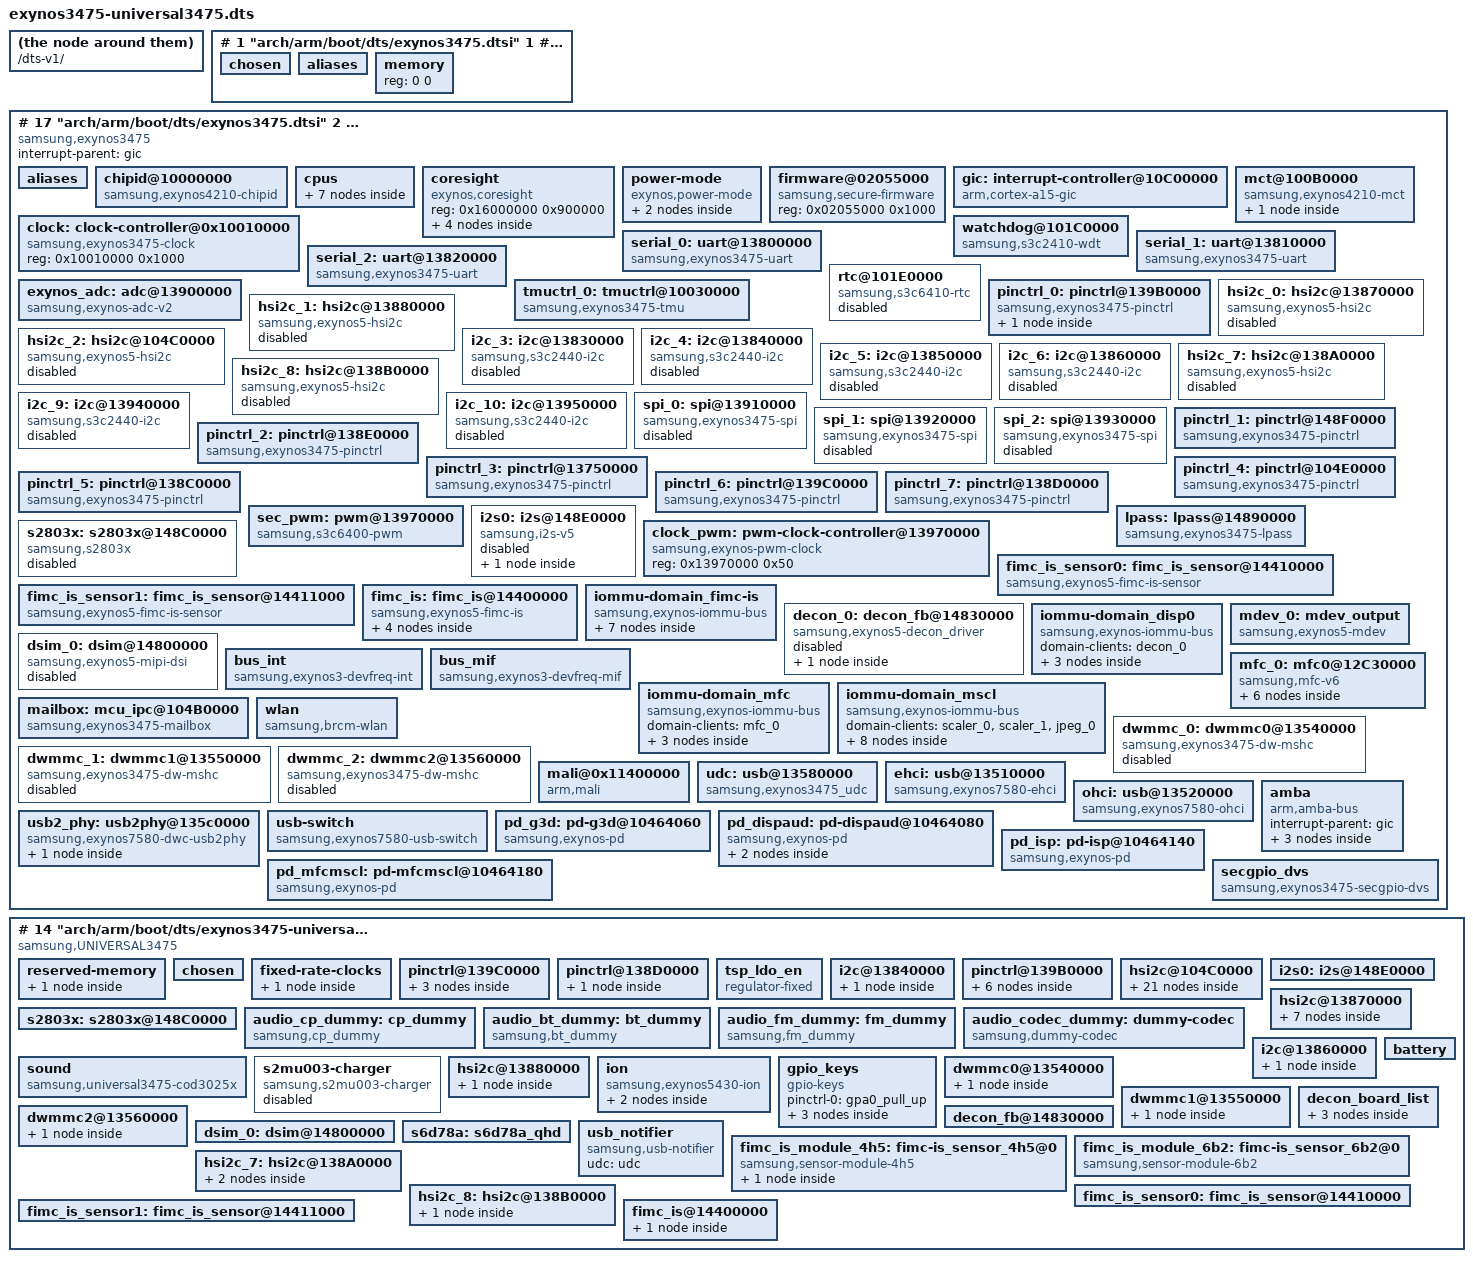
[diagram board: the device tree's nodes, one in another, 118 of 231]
# 1 "arch/arm/boot/dts/exynos3475-universal3475.dts"
# 1 "<command-line>"
# 1 "arch/arm/boot/dts/exynos3475-universal3475.dts"
# 12 "arch/arm/boot/dts/exynos3475-universal3475.dts"
/dts-v1/;
# 1 "arch/arm/boot/dts/exynos3475.dtsi" 1
# 16 "arch/arm/boot/dts/exynos3475.dtsi"
# 1 "arch/arm/boot/dts/skeleton.dtsi" 1






/ {
 #address-cells = <1>;
 #size-cells = <1>;
 chosen { };
 aliases { };
 memory { device_type = "memory"; reg = <0 0>; };
};
# 17 "arch/arm/boot/dts/exynos3475.dtsi" 2
# 1 "/home/dpi/qb5_8814/workspace/J2LTE_SWA_OPEN/android/kernel/exynos3475/arch/arm/boot/dts/include/dt-bindings/clock/exynos3475.h" 1
# 18 "arch/arm/boot/dts/exynos3475.dtsi" 2
# 1 "/home/dpi/qb5_8814/workspace/J2LTE_SWA_OPEN/android/kernel/exynos3475/arch/arm/boot/dts/include/dt-bindings/sysmmu/sysmmu.h" 1
# 19 "arch/arm/boot/dts/exynos3475.dtsi" 2
/include/ "exynos3475-pinctrl.dtsi"
/include/ "exynos3475-busmon.dtsi"
/ {
 compatible = "samsung,exynos3475";

 interrupt-parent = <&gic>;
 #address-cells = <1>;
 #size-cells = <1>;

 aliases {
  mdev0 = &mdev_0;
  dsim0 = &dsim_0;
  decon0 = &decon_0;
  pinctrl0 = &pinctrl_0;
  pinctrl1 = &pinctrl_1;
  pinctrl2 = &pinctrl_2;
  pinctrl3 = &pinctrl_3;
  pinctrl4 = &pinctrl_4;
  pinctrl5 = &pinctrl_5;
  pinctrl6 = &pinctrl_6;
  pinctrl7 = &pinctrl_7;
  uart0 = &serial_0;
  uart1 = &serial_1;
  uart2 = &serial_2;
  mshc0 = &dwmmc_0;
  mshc1 = &dwmmc_1;
  mshc2 = &dwmmc_2;
  spi0 = &spi_0;
  spi1 = &spi_1;
  spi2 = &spi_2;
  scaler0 = &scaler_0;
  scaler1 = &scaler_1;
  mfc0 = &mfc_0;
  jpeg0 = &jpeg_0;
  tmuctrl0 = &tmuctrl_0;
 };

 chipid@10000000 {
  compatible = "samsung,exynos4210-chipid";
  reg = <0x10000000 0x100>;
  reg2 = <0x10004000 0x100>;
 };

 cpus {
  #address-cells = <1>;
  #size-cells = <0>;
  idle-states {
   CPU_SLEEP_0: C1 {
    compatible = "arm,idle-state";
    desc = "ARM Clock gating(WFI)";
    exit-latency-us = <1>;
    min-residency-us = <500>;
    status = "enabled";
   };

                       CPU_SLEEP_1: C2 {
                               compatible = "arm,idle-state";
                               desc = "ARM Power down";
                               exit-latency-us = <50>;
                               min-residency-us = <2100>;
                               status = "enabled";
                       };
  };

  cpu@0 {
   device_type = "cpu";
   compatible = "arm,cortex-a7";
   reg = <0x0>;
   cpu-idle-states = <&CPU_SLEEP_0 &CPU_SLEEP_1>;
  };
  cpu@1 {
   device_type = "cpu";
   compatible = "arm,cortex-a7";
   reg = <0x1>;
   cpu-idle-states = <&CPU_SLEEP_0 &CPU_SLEEP_1>;
  };
  cpu@2 {
   device_type = "cpu";
   compatible = "arm,cortex-a7";
   reg = <0x2>;
   cpu-idle-states = <&CPU_SLEEP_0 &CPU_SLEEP_1>;
  };
  cpu@3 {
   device_type = "cpu";
   compatible = "arm,cortex-a7";
   reg = <0x3>;
   cpu-idle-states = <&CPU_SLEEP_0 &CPU_SLEEP_1>;
  };
 };

 coresight {
  compatible = "exynos,coresight";
  reg = <0x16000000 0x900000>;
  #address-cells = <1>;
  #size-cells = <0>;
  css_pc@0 {
   device_type = "cs";
   offset = <0x810000>;
  };
  css_pc@1 {
   device_type = "cs";
   offset = <0x812000>;
  };
  css_pc@2 {
   device_type = "cs";
   offset = <0x814000>;
  };
  css_pc@3 {
   device_type = "cs";
   offset = <0x816000>;
  };
 };

 power-mode {
  compatible = "exynos,power-mode";
  idle-ip0 = "13970000.pwm",
   "13900000.adc",
   "13870000.hsi2c",
   "13880000.hsi2c",
   "104c0000.hsi2c",
   "138a0000.hsi2c",
   "138b0000.hsi2c",
   "13830000.i2c",
   "13840000.i2c",
   "13850000.i2c",
   "13860000.i2c",
   "13940000.i2c",
   "13950000.i2c",
   "13910000.spi",
   "13920000.spi",
   "13930000.spi",
   "13540000.dwmmc0",
   "13550000.dwmmc1",
   "13560000.dwmmc2",
   "135c0000.usb2phy",
   "13650000.pdma0",
   "13660000.pdma1",
   "148D0000.adma";
  idle-ip1 = "pd-g3d", "pd-isp", "pd-dispaud", "pd-mfcmscl";
  sys_powermode {
   lpd: SYS_LPD {
    mode-index = <2>;
    idle-ip0-mask = <0xffc0fa80>;
    idle-ip1-mask = <0xfffffff4>;
   };
  };
 };

 firmware@02055000 {
  compatible = "samsung,secure-firmware";
  reg = <0x02055000 0x1000>;
 };

 gic:interrupt-controller@10C00000 {
  compatible = "arm,cortex-a15-gic";
  #interrupt-cells = <3>;
  interrupt-controller;
  reg = <0x10C01000 0x1000>,
   <0x10C02000 0x1000>,
   <0x10C04000 0x2000>,
   <0x10C06000 0x2000>;
  interrupts = <1 9 0xf04>;
 };

 clock: clock-controller@0x10010000 {
  compatible = "samsung,exynos3475-clock";
  reg = <0x10010000 0x1000>;
  #clock-cells = <1>;
 };

 mct@100B0000 {
  compatible = "samsung,exynos4210-mct";
  reg = <0x100B0000 0x800>;
  interrupt-controller;
  #interrupt-cells = <1>;
  interrupt-parent = <&mct_map>;
  interrupts = <0>, <1>, <2>, <3>,
        <4>, <5>, <6>, <7>,
        <8>, <9>, <10>, <11>;
  clocks = <&clock 437>, <&clock 318>;
  clock-names = "fin_pll", "mct";

  mct_map: mct-map {
   #interrupt-cells = <1>;
   #address-cells = <0>;
   #size-cells = <0>;
   interrupt-map = <0 &gic 0 102 0>,
     <1 &gic 0 103 0>,
     <2 &gic 0 104 0>,
     <3 &gic 0 105 0>,
     <4 &gic 0 106 0>,
     <5 &gic 0 107 0>,
     <6 &gic 0 108 0>,
     <7 &gic 0 109 0>,
     <8 &gic 0 110 0>,
     <9 &gic 0 111 0>,
     <10 &gic 0 112 0>,
     <11 &gic 0 113 0>;
  };
 };

 watchdog@101C0000 {
  compatible = "samsung,s3c2410-wdt";
  reg = <0x101C0000 0x100>;
  interrupts = <0 100 0>;
  clocks = <&clock 317>, <&clock 317>;
  clock-names = "rate_watchdog", "gate_watchdog";
  timeout-sec = <30>;
  pmu_wdt_reset_type = <4>;
 };

 serial_0: uart@13800000 {
  compatible = "samsung,exynos3475-uart";
  samsung,separate-uart-clk;
  reg = <0x13800000 0x100>;
  interrupts = <0 421 0>;
  pinctrl-names = "default";
  pinctrl-0 = <&uart0_bus>;
  clocks = <&clock 357>, <&clock 361>, <&clock 410>;
  clock-names = "gate_pclk0", "gate_uart0", "sclk_uart0";
 };

 serial_1: uart@13810000 {
  compatible = "samsung,exynos3475-uart";
  samsung,separate-uart-clk;
  reg = <0x13810000 0x100>;
  interrupts = <0 422 0>;
  pinctrl-names = "default";
  pinctrl-0 = <&uart1_bus>;
  clocks = <&clock 356>, <&clock 362>, <&clock 411>;
  clock-names = "gate_pclk1", "gate_uart1", "sclk_uart1";
 };

 serial_2: uart@13820000 {
  compatible = "samsung,exynos3475-uart";
  samsung,separate-uart-clk;
  reg = <0x13820000 0x100>;
  interrupts = <0 423 0>;
  pinctrl-names = "default";
  pinctrl-0 = <&uart2_bus>;
  clocks = <&clock 355>, <&clock 363>, <&clock 412>;
  clock-names = "gate_pclk2", "gate_uart2", "sclk_uart2";
 };

 rtc@101E0000 {
  compatible = "samsung,s3c6410-rtc";
  reg = <0x101E0000 0x100>;
  interrupts = <0 124 0>, <0 125 0>;
  clocks = <&clock 339>;
  clock-names = "gate_rtc";
  status = "disabled";
 };

 exynos_adc: adc@13900000 {
  compatible = "samsung,exynos-adc-v2";
  reg = <0x13900000 0x100>;
  interrupts = <0 439 0>;
  #io-channel-cells = <1>;
  io-channel-ranges;
  clocks = <&clock 354>;
  clock-names = "gate_adcif";
 };

 tmuctrl_0: tmuctrl@10030000 {
  compatible = "samsung,exynos3475-tmu";
  reg = <0x10030000 0x200>;
  interrupts = <0 435 0>;
 };

 pinctrl_0: pinctrl@139B0000 {
  compatible = "samsung,exynos3475-pinctrl";
  reg = <0x139B0000 0x1000>;
  interrupts = <0 0 0>, <0 1 0>, <0 2 0>, <0 3 0>,
    <0 4 0>, <0 5 0>, <0 6 0>, <0 7 0>,
    <0 8 0>, <0 9 0>, <0 10 0>, <0 11 0>,
    <0 12 0>, <0 13 0>, <0 14 0>, <0 15 0>;
  wakeup-interrupt-controller {
   compatible = "samsung,exynos4210-wakeup-eint";
   interrupt-parent = <&gic>;
   interrupts = <0 16 0>;
   samsung,eint-flt-conf;
  };
 };

 hsi2c_0: hsi2c@13870000 {
  compatible = "samsung,exynos5-hsi2c";
  samsung,check-transdone-int;
  reg = <0x13870000 0x1000>;
  interrupts = <0 428 0>;
  #address-cells = <1>;
  #size-cells = <0>;
  pinctrl-names = "default";
  pinctrl-0 = <&hs_i2c0_bus>;
  clocks = <&clock 307>, <&clock 307>;
  clock-names = "rate_hsi2c", "gate_hsi2c";
  samsung,scl-clk-stretching;
  gpio_sda = <&gpc1 0 0x1>;
  gpio_scl = <&gpc1 1 0x1>;
  status = "disabled";
 };

 hsi2c_1: hsi2c@13880000 {
  compatible = "samsung,exynos5-hsi2c";
  samsung,check-transdone-int;
  reg = <0x13880000 0x1000>;
  interrupts = <0 429 0>;
  #address-cells = <1>;
  #size-cells = <0>;
  pinctrl-names = "default";
  pinctrl-0 = <&hs_i2c1_bus>;
  clocks = <&clock 306>, <&clock 306>;
  clock-names = "rate_hsi2c", "gate_hsi2c";
  samsung,scl-clk-stretching;
  gpio_sda = <&gpc1 2 0x1>;
  gpio_scl = <&gpc1 3 0x1>;
  status = "disabled";
 };


 hsi2c_2: hsi2c@104C0000 {
  compatible = "samsung,exynos5-hsi2c";
  samsung,check-transdone-int;
  reg = <0x104C0000 0x2000>, <0x104b01C0 0x100>;
  interrupts = <0 384 0>,<0 394 0>;
  #address-cells = <1>;
  #size-cells = <0>;
  pinctrl-names = "default";
  pinctrl-0 = <&hs_i2c2_bus>;
  clocks = <&clock 286>, <&clock 286>;
  clock-names = "rate_hsi2c", "gate_hsi2c";
  samsung,scl-clk-stretching;
  gpio_sda = <&gpm0 0 0x1>;
  gpio_scl = <&gpm0 1 0x1>;
  status = "disabled";
 };

 i2c_3: i2c@13830000 {
  compatible = "samsung,s3c2440-i2c";
  reg = <0x13830000 0x1000>;
  interrupts = <0 424 0>;
  #address-cells = <1>;
  #size-cells = <0>;
  pinctrl-names = "default";
  pinctrl-0 = <&i2c3_bus>;
  clocks = <&clock 311>, <&clock 311>;
  clock-names = "rate_i2c","gate_i2c";
  status = "disabled";
 };

 i2c_4: i2c@13840000 {
  compatible = "samsung,s3c2440-i2c";
  reg = <0x13840000 0x1000>;
  interrupts = <0 425 0>;
  #address-cells = <1>;
  #size-cells = <0>;
  pinctrl-names = "default";
  pinctrl-0 = <&i2c4_bus>;
  clocks = <&clock 310>, <&clock 310>;
  clock-names = "rate_i2c","gate_i2c";
  status = "disabled";
 };

 i2c_5: i2c@13850000 {
  compatible = "samsung,s3c2440-i2c";
  reg = <0x13850000 0x1000>;
  interrupts = <0 426 0>;
  #address-cells = <1>;
  #size-cells = <0>;
  pinctrl-names = "default";
  pinctrl-0 = <&i2c5_bus>;
  clocks = <&clock 309>, <&clock 309>;
  clock-names = "rate_i2c","gate_i2c";
  status = "disabled";
 };

 i2c_6: i2c@13860000 {
  compatible = "samsung,s3c2440-i2c";
  reg = <0x13860000 0x1000>;
  interrupts = <0 427 0>;
  #address-cells = <1>;
  #size-cells = <0>;
  pinctrl-names = "default";
  pinctrl-0 = <&i2c6_bus>;
  clocks = <&clock 308>, <&clock 308>;
  clock-names = "rate_i2c","gate_i2c";
  status = "disabled";
 };

 hsi2c_7: hsi2c@138A0000 {
  compatible = "samsung,exynos5-hsi2c";
  samsung,check-transdone-int;
  reg = <0x138A0000 0x1000>;
  interrupts = <0 430 0>;
  #address-cells = <1>;
  #size-cells = <0>;
  pinctrl-names = "default";
  pinctrl-0 = <&hs_i2c7_bus>;
  clocks = <&clock 305>, <&clock 305>;
  clock-names = "rate_hsi2c", "gate_hsi2c";
  samsung,scl-clk-stretching;
  gpio_sda = <&gpf0 0 0x1>;
  gpio_scl = <&gpf0 1 0x1>;
  status = "disabled";
 };

 hsi2c_8: hsi2c@138B0000 {
  compatible = "samsung,exynos5-hsi2c";
  samsung,check-transdone-int;
  reg = <0x138B0000 0x1000>;
  interrupts = <0 431 0>;
  #address-cells = <1>;
  #size-cells = <0>;
  pinctrl-names = "default";
  pinctrl-0 = <&hs_i2c8_bus>;
  clocks = <&clock 304>, <&clock 304>;
  clock-names = "rate_hsi2c", "gate_hsi2c";
  samsung,scl-clk-stretching;
  gpio_sda = <&gpf0 2 0x1>;
  gpio_scl = <&gpf0 3 0x1>;
  status = "disabled";
 };

 i2c_9: i2c@13940000 {
  compatible = "samsung,s3c2440-i2c";
  reg = <0x13940000 0x1000>;
  interrupts = <0 436 0>;
  #address-cells = <1>;
  #size-cells = <0>;
  pinctrl-names = "default";
  pinctrl-0 = <&i2c9_bus>;
  clocks = <&clock 350>, <&clock 350>;
  clock-names = "rate_i2c","gate_i2c";
  status = "disabled";
 };

 i2c_10: i2c@13950000 {
  compatible = "samsung,s3c2440-i2c";
  reg = <0x13950000 0x1000>;
  interrupts = <0 437 0>;
  #address-cells = <1>;
  #size-cells = <0>;
  pinctrl-names = "default";
  pinctrl-0 = <&i2c10_bus>;
  clocks = <&clock 349>, <&clock 349>;
  clock-names = "rate_i2c","gate_i2c";
  status = "disabled";
 };

 spi_0: spi@13910000 {
  samsung,ignore-sclk-gate;
  compatible = "samsung,exynos3475-spi";
  reg = <0x13910000 0x100>;
  interrupts = <0 432 0>;






  swap-mode;
  #address-cells = <1>;
  #size-cells = <0>;
  clocks = <&clock 353>, <&clock 358>;
  clock-names = "spi", "spi_busclk0";
  pinctrl-names = "default";
  pinctrl-0 = <&spi0_bus_0 &spi0_bus_1>;
  status = "disabled";
 };

 spi_1: spi@13920000 {
  samsung,ignore-sclk-gate;
  compatible = "samsung,exynos3475-spi";
  reg = <0x13920000 0x100>;
  interrupts = <0 433 0>;






  swap-mode;
  #address-cells = <1>;
  #size-cells = <0>;
  clocks = <&clock 352>, <&clock 359>;
  clock-names = "spi", "spi_busclk0";
  pinctrl-names = "default";
  pinctrl-0 = <&spi1_bus>;
  status = "disabled";
 };

 spi_2: spi@13930000 {
  samsung,ignore-sclk-gate;
  compatible = "samsung,exynos3475-spi";
  reg = <0x13930000 0x100>;
  interrupts = <0 434 0>;






  #address-cells = <1>;
  #size-cells = <0>;
  clocks = <&clock 351>, <&clock 360>;
  clock-names = "spi", "spi_busclk0";
  pinctrl-names = "default";
  pinctrl-0 = <&spi2_bus>;
  status = "disabled";
 };

 pinctrl_1: pinctrl@148F0000 {
  compatible = "samsung,exynos3475-pinctrl";
  reg = <0x148F0000 0x1000>;
  interrupts = <0 68 0>;
 };

 pinctrl_2: pinctrl@138E0000 {
  compatible = "samsung,exynos3475-pinctrl";
  reg = <0x138E0000 0x1000>;
  interrupts = <0 438 0>;
 };

 pinctrl_3: pinctrl@13750000 {
  compatible = "samsung,exynos3475-pinctrl";
  reg = <0x13750000 0x1000>;
  interrupts = <0 250 0>;
 };

 pinctrl_4: pinctrl@104E0000 {
  compatible = "samsung,exynos3475-pinctrl";
  reg = <0x104E0000 0x1000>;
  interrupts = <0 385 0>;
 };

 pinctrl_5: pinctrl@138C0000 {
  compatible = "samsung,exynos3475-pinctrl";
  reg = <0x138C0000 0x1000>;
  interrupts = <0 115 0>;
 };

 pinctrl_6: pinctrl@139C0000 {
  compatible = "samsung,exynos3475-pinctrl";
  reg = <0x139C0000 0x1000>;
  interrupts = <0 440 0>;
 };

 pinctrl_7: pinctrl@138D0000 {
  compatible = "samsung,exynos3475-pinctrl";
  reg = <0x138D0000 0x1000>;
  interrupts = <0 116 0>;
 };

 sec_pwm: pwm@13970000 {
  compatible = "samsung,s3c6400-pwm";
  reg = <0x13970000 0x1000>;
  #pwm-cells = <3>;
  clocks = <&clock 348>,
         <&clock_pwm 1>, <&clock_pwm 2>,
         <&clock_pwm 5>, <&clock_pwm 6>,
         <&clock_pwm 7>, <&clock_pwm 8>,
         <&clock_pwm 10>, <&clock_pwm 11>,
         <&clock_pwm 12>, <&clock_pwm 13>;
  clock-names = "gate_timers",
   "pwm-scaler0", "pwm-scaler1",
   "pwm-tdiv0", "pwm-tdiv1",
   "pwm-tdiv2", "pwm-tdiv3",
   "pwm-tin0", "pwm-tin1",
   "pwm-tin2", "pwm-tin3";
  status = "ok";
  clock-control = <1>;
 };

 lpass: lpass@14890000 {
  compatible = "samsung,exynos3475-lpass";
  reg = <0x14890000 0x1040>;
  clocks = <&clock 195>,
   <&clock 437>,
   <&clock 62>,
   <&clock 64>,
   <&clock 67>,
   <&clock 68>,
   <&clock 69>,
   <&clock 70>,
   <&clock 72>;

  clock-names = "fout_aud_pll", "fin_pll", "mout_aud_pll_user",
   "mout_sclk_mi2s", "dout_sclk_mi2s",
   "dout_sclk_mixer", "pclk_dispaud_p", "aclk_aud",
   "aclk_dispaud_d";

  samsung,power-domain = <&spd_aud>;
  status = "okay";
 };

 s2803x: s2803x@148C0000 {
  compatible = "samsung,s2803x";
  reg = <0x148C0000 0x200>;
  clocks = <&clock 80>,
    <&clock 81>,
    <&clock 83>,
    <&clock 82>,
    <&clock 68>,
    <&clock 70>;

  clock-names = "audmixer_sysclk", "audmixer_bclk0",
    "audmixer_bclk1", "audmixer_bclk2",
    "audmixer_dout", "audmixer_aclk";

  samsung,lpass-subip;
  status = "disabled";
 };

 i2s0: i2s@148E0000 {
  compatible = "samsung,i2s-v5";
  reg = <0x148E0000 0x100>;
  dmas = <&adma 0
   &adma 2>;
  dma-names = "tx", "rx";
  interrupts = <0 205 0>;
  clocks = <&clock 70>,
    <&clock 79>,
    <&clock 79>;
  clock-names = "iis", "i2s_opclk0", "i2s_opclk1";
  samsung,supports-rstclr;
  samsung,supports-secdai;
  samsung,i2s-str;
  samsung,lpass-subip;
  status = "disabled";
  i2s-sec {
   dmas = <&adma 1>;
   dma-names = "tx-sec";
   clocks = <&clock 70>,
     <&clock 79>,
     <&clock 79>;
   clock-names = "iis", "i2s_opclk0", "i2s_opclk1";
  };
 };

 clock_pwm: pwm-clock-controller@13970000 {
  compatible = "samsung,exynos-pwm-clock";
  reg = <0x13970000 0x50>;
  #clock-cells = <1>;
 };

 fimc_is_sensor0: fimc_is_sensor@14410000 {
  compatible = "samsung,exynos5-fimc-is-sensor";
  #pb-id-cells = <4>;
  interrupts = <0 138 0>,
     <0 144 0>;

  samsung,power-domain = <&pd_isp>;

  clock-names = "phyclk_csi_link0_rx_byte_clk_hs0",

    "mout_sclk_isp_sensor0",

    "dout_sclk_isp_sensor0_a",
    "dout_sclk_isp_sensor0_b",
    "dout_sclk_isp_sensor1_a",
    "dout_sclk_isp_sensor1_b",

    "sclk_isp_sensor0",

    "oscclk";

  clocks = <&clock 179>,

    <&clock 387>,

    <&clock 413>,
    <&clock 414>,
    <&clock 415>,
    <&clock 416>,

    <&clock 435>,

    <&clock 437>;
 };

 fimc_is_sensor1: fimc_is_sensor@14411000 {
  compatible = "samsung,exynos5-fimc-is-sensor";
  #pb-id-cells = <4>;
  interrupts = <0 138 0>,
     <0 144 0>;

  samsung,power-domain = <&pd_isp>;

  clock-names = "phyclk_csi_link0_rx_byte_clk_hs0",

    "mout_sclk_isp_sensor1",

    "dout_sclk_isp_sensor0_a",
    "dout_sclk_isp_sensor0_b",
    "dout_sclk_isp_sensor1_a",
    "dout_sclk_isp_sensor1_b",

    "sclk_isp_sensor1",

    "oscclk";


  clocks = <&clock 179>,

    <&clock 388>,

    <&clock 413>,
    <&clock 414>,
    <&clock 415>,
    <&clock 416>,

    <&clock 436>,

    <&clock 437>;
 };

 fimc_is: fimc_is@14400000 {
  compatible = "samsung,exynos5-fimc-is";
  #pb-id-cells = <4>;
  reg = <0x14400000 0x10000>,
    <0x14430000 0x10000>,
    <0x14440000 0x10000>,
    <0x14480000 0x10000>;
  interrupts = <0 139 0>,
     <0 140 0>,
     <0 141 0>,
     <0 142 0>,
     <0 143 0>;

  samsung,power-domain = <&pd_isp>;

  clocks = <&clock 171>,
    <&clock 173>,
    <&clock 174>,
    <&clock 175>,
    <&clock 176>,
    <&clock 177>,
    <&clock 179>,

    <&clock 437>;

  clock-names = "mout_aclk_isp_300_user",
       "dout_pclk_isp_150",
       "aclk_isp_300_aclk_isp_d",
       "aclk_isp_300_aclk_ppmu",
       "aclk_isp_300_aclk_fd",
       "aclk_isp_300_aclk_is",
       "phyclk_csi_link0_rx_byte_clk_hs0",

       "oscclk";


  clk_gate_strs = "gate_3aa1",
       "gate_isp",
       "gate_drc",
       "gate_scalerc",
       "gate_dis",
       "gate_3dnr",
       "gate_scalerp",
       "gate_fd",
       "gate_3aa0";

  clk_gate_ctrl {

   group0 {
   };

   group1 {

   };

   group2 {
   };
  };
 };

 iommu-domain_fimc-is {
  compatible = "samsung,exynos-iommu-bus";
  #address-cells = <1>;
  #size-cells = <1>;
  ranges;

  domain-clients = <&fimc_is>,
    <&fimc_is_sensor0>,
    <&fimc_is_sensor1>;

  sysmmu_isp0: sysmmu@0x144A0000 {
    compatible = "samsung,exynos7420-sysmmu";
    reg = <0x144A0000 0x1000>;
    interrupts = <0 128 0>;
    clocks = <&clock 177>;
    clock-names = "aclk";
    sysmmu,block-when-stop;
    pb-info {
    pb@0 {
      master_axi_id_list = <&fimc_is (1) ((0) + 0x8000) ((1) + 0x8000) ((5) + 0x8000)>,
        <&fimc_is_sensor0 (1) ((0) + 0x8000) ((1) + 0x8000) ((5) + 0x8000)>,
        <&fimc_is_sensor1 (1) ((0) + 0x8000) ((1) + 0x8000) ((5) + 0x8000)>;
    };
    pb@1 {
      master_axi_id_list = <&fimc_is ((2) + 0x8000) ((6) + 0x8000) ((10) + 0x8000) 65536>;
    };
    };
   };

  sysmmu_isp1: sysmmu@0x144B0000 {
    compatible = "samsung,exynos7420-sysmmu";
    reg = <0x144B0000 0x1000>;
    interrupts = <0 131 0>;
    clocks = <&clock 176>;
    clock-names = "aclk";
    sysmmu,block-when-stop;
    pb-info {
     pb@0 {
      master_axi_id_list = <&fimc_is 65536 65536 65536 65536>;
     };
   };
  };
 };


 decon_0: decon_fb@14830000 {
  compatible = "samsung,exynos5-decon_driver";
  #pb-id-cells = <0>;
  reg = <0x14830000 0x10000>;


  interrupts = <0 195 0>, <0 196 0>, <0 197 0>;


  clocks =<&clock 72>, <&clock 71>,
         <&clock 75>, <&clock 76>,
         <&clock 65>, <&clock 66>,
         <&clock 58>, <&clock 59>,
         <&clock 208>, <&clock 218>,
         <&clock 207>, <&clock 217>,
         <&clock 193>;

  clock-names =
   "aclk_dispaud_d", "aclk_disp",
   "decon0_vclk", "decon0_eclk",
   "d_decon0_vclk", "d_decon0_eclk",
   "m_sclk_decon_int_vclk_user", "m_sclk_decon_int_eclk_user",
   "m_sclk_disp_decon0_vclk", "d_sclk_disp_decon0_vclk",
   "m_sclk_disp_decon0_eclk", "d_sclk_disp_decon0_eclk",
   "mif_pll";

  ip_ver = <4>;
  max_win = <3>;
  n_sink_pad = <3>;
  n_src_pad = <1>;
  default_win = <0>;
  psr_mode = <0>;
  trig_mode = <0>;
  dsi_mode = <0>;

  samsung,power-domain = <&spd_disp>;
  status = "disabled";

                #address-cells = <1>;
                #size-cells = <1>;
  ranges;

  cam-stat {

   reg = <0x0 0x10464144 0x0 0x4>;
  };

 };

 iommu-domain_disp0 {
  compatible = "samsung,exynos-iommu-bus";
  #address-cells = <1>;
  #size-cells = <1>;
  ranges;

  domain-clients = <&decon_0>;

  sysmmu_disp: sysmmu@0x14860000 {
    compatible = "samsung,exynos7420-sysmmu";
    reg = <0x14860000 0x1000>;
    interrupts = <0 192 0>;
    sysmmu,block-when-stop;
    pb-info {
     pb@0 {
      master_axi_id_list = <&decon_0>;
     };
   };
  };
 };

 mdev_0: mdev_output {
  compatible = "samsung,exynos5-mdev";
 };

 dsim_0: dsim@14800000 {
  compatible = "samsung,exynos5-mipi-dsi";
  reg = <0x14800000 0x1000>;
  interrupts = <0 201 0>;

  clocks = <&clock 77>, <&clock 78>;

  clock-names = "mipi0_bit", "mipi0_rx";

  samsung,power-domain = <&spd_disp>;

  status = "disabled";
 };

 bus_int {
  compatible = "samsung,exynos3-devfreq-int";

  bus_type_int = <0>;

  pm_qos_class = <4>;
  cal_qos_max = <00 275000>;
  default_qos = <00 275000>;
  initial_freq = <00 275000>;
  polling_period = <0>;
 };

 bus_mif {
  compatible = "samsung,exynos3-devfreq-mif";

  bus_type_mif = <1>;

  pm_qos_class = <5>;
  pm_qos_class_max = <6>;
  cal_qos_max = <00 666000>;
  default_qos = <00 413000>;
  initial_freq = <00 666000>;
  polling_period = <0>;
 };

 mfc_0: mfc0@12C30000 {
  compatible = "samsung,mfc-v6";
  #pb-id-cells = <0>;
  reg = <0x12C30000 0x10000>;
  interrupts = <0 358 0>;

  clock-names = "aclk_mfcmscl_333_aclk_mfcmscl_d", "aclk_mfcmscl_200_aclk_mfc";
  clocks = <&clock 184>, <&clock 191>;

  samsung,power-domain = <&pd_mfcmscl>;
  status = "ok";
  ip_ver = <13>;
  clock_rate = <200000000>;
  min_rate = <100000>;

  num_qos_steps = <5>;
  mfc_qos_table {
   mfc_qos_variant_0 {
    thrd_mb = <0>;
    freq_mfc = <100000>;
    freq_int = <275000>;
    freq_mif = <413000>;
    freq_cpu = <0>;
    freq_kfc = <0>;
   };
   mfc_qos_variant_1 {
    thrd_mb = <108000>;
    freq_mfc = <100000>;
    freq_int = <275000>;
    freq_mif = <413000>;
    freq_cpu = <0>;
    freq_kfc = <0>;
    has_enc_table = <0>;
   };
   mfc_qos_variant_2 {
    thrd_mb = <244800>;
    freq_mfc = <200000>;
    freq_int = <275000>;
    freq_mif = <559000>;
    freq_cpu = <0>;
    freq_kfc = <0>;
    has_enc_table = <0>;
   };
   mfc_qos_variant_3 {
    thrd_mb = <244800>;
    freq_mfc = <160000>;
    freq_int = <275000>;
    freq_mif = <413000>;
    freq_cpu = <0>;
    freq_kfc = <0>;
    has_enc_table = <1>;
   };
   mfc_qos_variant_4 {
    thrd_mb = <489600>;
    freq_mfc = <200000>;
    freq_int = <275000>;
    freq_mif = <559000>;
    freq_cpu = <0>;
    freq_kfc = <0>;
    has_enc_table = <0>;
   };
  };
 };

 iommu-domain_mfc {
  compatible = "samsung,exynos-iommu-bus";
  #address-cells = <1>;
  #size-cells = <1>;
  ranges;

  domain-clients = <&mfc_0>;

  sysmmu_mfc: sysmmu@0x12C90000 {
    compatible = "samsung,exynos7420-sysmmu";
    reg = <0x12C90000 0x1000>;
    interrupts = <0 359 0>;
    sysmmu,block-when-stop;
    pb-info {
     pb@0 {
      master_axi_id_list = <&mfc_0>;
     };
   };
  };
 };

 iommu-domain_mscl {
  compatible = "samsung,exynos-iommu-bus";
  #address-cells = <1>;
  #size-cells = <1>;
  ranges;

  domain-clients = <&scaler_0>, <&scaler_1>, <&jpeg_0>;

  scaler_0: scaler@0x12C10000 {
   compatible = "samsung,exynos5-scaler";
   #pb-id-cells = <0>;
   reg = <0x12C10000 0x1300>;
   interrupts = <0 353 0>;
   samsung,power-domain = <&pd_mfcmscl>;
   clocks = <&clock 185>;
   clock-names = "gate";
  };

  scaler_1: scaler@0x12C00000 {
   compatible = "samsung,exynos5-scaler";
   #pb-id-cells = <0>;
   reg = <0x12C00000 0x1300>;
   interrupts = <0 352 0>;
   samsung,power-domain = <&pd_mfcmscl>;
   clocks = <&clock 186>;
   clock-names = "gate";
  };

  jpeg_0: jpeg@12C20000{
   compatible = "samsung,exynos-jpeg";
   #pb-id-cells = <0>;
   reg = <0x12C20000 0x1000>;
   interrupts = <0 357 0>;
   clocks = <&clock 187>;
   clock-names = "gate";
   ip_ver = <2>;
   samsung,power-domain = <&pd_mfcmscl>;
  };

  sysmmu_mscl: sysmmu@0x12C80000 {
    compatible = "samsung,exynos7420-sysmmu";
    reg = <0x12C80000 0x1000>;
    interrupts = <0 354 0>;
    clocks = <&clock 184>, <&clock 188>;
    clock-names = "aclk", "pclk";

    sysmmu,block-when-stop;
    pb-info {
     pb@0 {
      master_axi_id_list = <&scaler_0>;
     };
     pb@1 {
      master_axi_id_list = <&scaler_1>;
     };
     pb@2 {
      master_axi_id_list = <&jpeg_0>;
     };
   };
  };
 };

 mailbox: mcu_ipc@104B0000 {
  compatible = "samsung,exynos3475-mailbox";
  reg = <0x104B0000 0x180>;
  mcu,name = "mcu_ipc";
  mcu,id = <1>;
  interrupts = <0 383 0 >;
 };

 wlan {
  compatible = "samsung,brcm-wlan";
  gpios = <&gpd1 4 0x1
  &gpa1 5 0x1 >;
  pinctrl-names = "default";
  pinctrl-0 = <&cfg_wlanen &cfg_wlanhostwake>;
  status = "okay";
  };

 dwmmc_0: dwmmc0@13540000 {
  compatible = "samsung,exynos3475-dw-mshc";
  reg = <0x13540000 0x2000>;
  interrupts = <0 245 0>;
  #address-cells = <1>;
  #size-cells = <0>;
  clocks = <&clock 117>, <&clock 426>,
         <&clock 398>, <&clock 399>;
  clock-names = "biu", "gate_ciu",
   "dout_mmc_a", "dout_mmc_b";
  status = "disabled";
 };

 dwmmc_1: dwmmc1@13550000 {
  compatible = "samsung,exynos3475-dw-mshc";
  reg = <0x13550000 0x2000>;
  interrupts = <0 246 0>;
  #address-cells = <1>;
  #size-cells = <0>;
  clocks = <&clock 116>, <&clock 427>,
   <&clock 400>, <&clock 401>;
  clock-names = "biu", "gate_ciu",
   "dout_mmc_a", "dout_mmc_b";
  status = "disabled";
 };

 dwmmc_2: dwmmc2@13560000 {
  compatible = "samsung,exynos3475-dw-mshc";
  reg = <0x13560000 0x2000>;
  interrupts = <0 247 0>;
  #address-cells = <1>;
  #size-cells = <0>;
  clocks = <&clock 115>, <&clock 428>,
   <&clock 402>, <&clock 403>;
  clock-names = "biu", "gate_ciu",
   "dout_mmc_a", "dout_mmc_b";
  status = "disabled";
 };

 mali@0x11400000 {
  compatible = "arm,mali";
  reg = <0x11400000 0x5000>;
  interrupts = <0 282 0>, <0 283 0>, <0 281 0>;
  interrupt-names = "JOB", "MMU", "GPU";
  clocks = <&clock 437>, <&clock 130>, <&clock 131>, <&clock 132>, <&clock 139>, <&clock 395>, <&clock 423>;
  clock-names = "fin_pll", "fout_g3d_pll", "mout_aclk_g3d_400_user",
   "mout_aclk_g3d_667", "aclk_g3d", "dout_aclk_g3d_400", "aclk_g3d_400";
  samsung,power-domain = <&pd_g3d>;
 };

 udc: usb@13580000 {
  compatible = "samsung,exynos3475_udc";
  reg = <0x13580000 0x1000>;
  interrupts = <0 238 0>;

  clocks = <&clock 114>, <&clock 113>, <&clock 112>,
    <&clock 110>, <&clock 102>, <&clock 99>,
    <&clock 107>, <&clock 106>;
  clock-names = "otg_aclk", "otg_hclk", "upsizer_otg",
   "xiu_d_fsys1", "upsizer_fsys1", "upsizer_ahb_usbhs",
   "ahb_usbhs", "ahb2axi_usbhs";
  usb-phy = <&usb2_phy>;
 };

 ehci: usb@13510000 {
  compatible = "samsung,exynos7580-ehci";
  reg = <0x13510000 0x100>;
  interrupts = <0 239 0>;
  clocks = <&clock 114>, <&clock 110>, <&clock 107>,
         <&clock 106>, <&clock 102>, <&clock 99>, <&clock 119>;
  clock-names = "otg_aclk", "xiu_d_fsys1", "ahb_usbhs",
   "ahb2axi_usbhs", "upsizer_fsys1", "upsizer_ahb_usbhs","usbhost20";
  usb-phy = <&usb2_phy>;
  status = "ok";
 };

 ohci: usb@13520000 {
  compatible = "samsung,exynos7580-ohci";
  reg = <0x13520000 0x100>;
  clocks = <&clock 114>, <&clock 110>, <&clock 107>,
         <&clock 106>, <&clock 102>, <&clock 99>, <&clock 119>;
  clock-names = "otg_aclk", "xiu_d_fsys1", "ahb_usbhs",
   "ahb2axi_usbhs", "upsizer_fsys1", "upsizer_ahb_usbhs", "usbhost20";
  interrupts = <0 239 0>;
  usb-phy = <&usb2_phy>;
  status = "ok";
 };

 usb2_phy: usb2phy@135c0000 {
  compatible = "samsung,exynos7580-dwc-usb2phy";
  #address-cells = <1>;
  #size-cells = <1>;
  reg = <0x135c0000 0x100>;
  clocks = <&clock 85>, <&clock 93>, <&clock 114>, <&clock 113>,
    <&clock 112>, <&clock 110>, <&clock 102>, <&clock 99>,
    <&clock 126>, <&clock 127>, <&clock 128>;
  clock-names = "usb_pll", "phy_otg", "otg_aclk", "otg_hclk",
      "upsizer_otg", "xiu_d_fsys1", "upsizer_fsys1", "upsizer_ahb_usbhs",
   "freeclk", "phyclk", "clk48mohci";
  ranges;

  usbphy-sys {
   reg = <0x10460738 0xC>,
    <0x13721020 0xC>;
  };
 };

 usb-switch {
  compatible = "samsung,exynos7580-usb-switch";
  ehci = <&ehci>;
  ohci = <&ohci>;
 };

 pd_g3d: pd-g3d@10464060 {
  compatible = "samsung,exynos-pd";
  reg = <0x10464060 0x20>;
  pd-option = <0x1>;
  bts-status = "enabled";
 };

 pd_dispaud: pd-dispaud@10464080 {
  compatible = "samsung,exynos-pd";
  reg = <0x10464080 0x20>;
  pd-option = <0x2>;
  bts-status = "enabled";

  spd_aud: spd-aud@10464080 {
   compatible = "samsung,exynos-spd";
  };

  spd_disp: spd-disp@10464080 {
   compatible = "samsung,exynos-spd";
  };
 };

 pd_isp: pd-isp@10464140 {
  compatible = "samsung,exynos-pd";
  reg = <0x10464140 0x20>;
  pd-option = <0x2>;
  bts-status = "enabled";
 };

 pd_mfcmscl: pd-mfcmscl@10464180 {
  compatible = "samsung,exynos-pd";
  reg = <0x10464180 0x20>;
  pd-option = <0x2>;
  bts-status = "enabled";
 };

 amba {
  #address-cells = <1>;
  #size-cells = <1>;
  compatible = "arm,amba-bus";
  interrupt-parent = <&gic>;
  ranges;

  pdma0: pdma0@13650000 {
   compatible = "arm,pl330", "arm,primecell";
   reg = <0x13650000 0x1000>;
   interrupts = <0 228 0>;
   clocks = <&clock 121>;
   clock-names = "apb_pclk";
   #dma-cells = <1>;
   #dma-channels = <8>;
   #dma-requests = <32>;
  };

  pdma1: pdma1@13660000 {
   compatible = "arm,pl330", "arm,primecell";
   reg = <0x13660000 0x1000>;
   interrupts = <0 229 0>;
   clocks = <&clock 120>;
   clock-names = "apb_pclk";
   #dma-cells = <1>;
   #dma-channels = <4>;
   #dma-requests = <32>;
  };

  adma: adma@148D0000 {
   compatible = "arm,pl330", "arm,primecell";
   reg = <0x148D0000 0x1000>;
   interrupts = <0 204 0>;
   clocks = <&clock 70>;
   clock-names = "apb_pclk";
   #dma-cells = <1>;
   #dma-channels = <4>;
   #dma-requests = <32>;
   samsung,reset-reg = <0x14891000>;
   samsung,reset-bit = <2>;
   samsung,reset-high;
  };
 };

 secgpio_dvs {
  compatible = "samsung,exynos3475-secgpio-dvs";
  status = "okay";
 };
};
# 14 "arch/arm/boot/dts/exynos3475-universal3475.dts" 2

/ {
 model = "Samsung UNIVERSAL3475 board based on EXYNOS3475";
 compatible = "samsung,UNIVERSAL3475", "samsung,exynos3475";

 reserved-memory {
  #address-cells = <1>;
  #size-cells = <1>;
  ranges;

  mfc_nfw {
   compatible = "exynos5433-ion,mfc_nfw";
   size = <0x100000>;
   alignment = <0x100000>;
   id = <12>;
  };
 };

 chosen {
  bootargs = "console=ttySAC2,115200 vmalloc=256M ess_setup=0x26000000";
 };

 fixed-rate-clocks {
  oscclk {
   compatible = "samsung,exynos3475-oscclk";
   clock-frequency = <26000000>;
  };
 };

 pinctrl@139C0000 {
  attn_irq: attn-irq {
   samsung,pins = "gpd1-5";
   samsung,pin-function = <0xf>;
   samsung,pin-pud = <0>;
   samsung,pin-drv = <0>;
  };

  attn_input: attn-input {
   samsung,pins = "gpd1-5";
   samsung,pin-function = <0>;
   samsung,pin-pud = <1>;
   samsung,pin-drv = <0>;
  };
 };

 pinctrl@138D0000 {
  i2c_pdn_off: i2c-pdn_off {
   samsung,pins = "gpc3-1", "gpc3-0";
   samsung,pin-con-pdn = <2>;
   samsung,pin-pud-pdn = <1>;
  };
 };

 tsp_ldo_en {
  compatible = "regulator-fixed";
  regulator-name = "tsp_avdd";
  regulator-min-microvolt = <3000000>;
  regulator-max-microvolt = <3000000>;
  gpio = <&gpc3 2 0>;
  enable-active-high;
  };

 i2c@13840000 {
  samsung,i2c-sda-delay = <100>;
  samsung,i2c-max-bus-freq = <400000>;
  status = "okay";
  touchscreen@20 {
   compatible = "zinitix,bt532_ts_device";
   reg = <0x20>;
   pinctrl-names = "on_state", "off_state";
   pinctrl-0 = <&attn_irq>;
   pinctrl-1 = <&attn_input &i2c_pdn_off>;
   zinitix,irq_gpio = <&gpd1 5 0>;
   zinitix,gpio_ldo_en;
   zinitix,regulator_avdd = "tsp_avdd";
   zinitix,x_resolution = <540>;
   zinitix,y_resolution = <960>;
   zinitix,page_size = <128>;
   zinitix,orientation = <0>;
   zinitix,firmware_name = "tsp_zinitix/bt532_gt58.fw";
  };
 };

 pinctrl@139B0000 {
  pmic_irq: pmic-irq {
   samsung,pins = "gpa1-2";
   samsung,pin-pud = <3>;
   samsung,pin-drv = <3>;
  };

  if_irq: if-irq {
   samsung,pins = "gpa0-2";
   samsung,pin-pud = <3>;
   samsung,pin-drv = <3>;
  };

  cod3025_irq: cod3025-irq {
   samsung,pins = "gpa0-6";
   samsung,pin-pud = <3>;
   samsung,pin-drv = <3>;
  };
 };

 pinctrl@139C0000 {

  pm_wrsti: pm-wrsti {
   samsung,pins = "gpd0-1";
   samsung,pin-con-pdn = <3>;
  };
 };

 hsi2c@104C0000 {
  status = "okay";
  samsung,hs-mode;
  clock-frequency = <1500000>;
  samsung,hsi2c-batcher;
  #address-cells = <1>;
  #size-cells = <0>;
  s2mpu04_pmic@66 {
   compatible = "samsung,s2mpu04-pmic";
   reg = <0x66>;
   ten-bit-address;
   interrupts = <2 0 0>;
   interrupt-parent = <&gpa1>;
   pinctrl-names = "default";
   pinctrl-0 = <&pmic_irq &pm_wrsti>;

   wtsr_en = <1>;
   smpl_en = <1>;
   wtsr_timer_val = <3>;
   smpl_timer_val = <4>;
   check_jigon = <0>;

   init_time,sec = <0>;
   init_time,min = <0>;
   init_time,hour = <12>;
   init_time,mday = <1>;
   init_time,mon = <0>;
   init_time,year = <115>;
   init_time,wday = <4>;

   regulators {
    buck1_reg: BUCK1 {
     regulator-name = "vdd_core";
     regulator-min-microvolt = <600000>;
     regulator-max-microvolt = <1400000>;
     regulator-always-on;
     regulator-boot-on;
     regulator-ramp-delay = <12000>;
     regulator-initial-mode = <3>;
     regulator-expected-consumer = <4>;
    };

    buck2_reg: BUCK2 {
     regulator-name = "vdd_lldo";
     regulator-min-microvolt = <1200000>;
     regulator-max-microvolt = <1500000>;
     regulator-always-on;
     regulator-boot-on;
     regulator-ramp-delay = <12000>;
     regulator-initial-mode = <3>;
    };

    buck3_reg: BUCK3 {
     regulator-name = "vdd_mldo";
     regulator-min-microvolt = <1800000>;
     regulator-max-microvolt = <2100000>;
     regulator-always-on;
     regulator-boot-on;
     regulator-ramp-delay = <12000>;
     regulator-initial-mode = <3>;
    };

    ldo1_reg: LDO1 {
     regulator-name = "vdd_ldo1";
     regulator-min-microvolt = <900000>;
     regulator-max-microvolt = <1200000>;
     regulator-always-on;
     regulator-boot-on;
     regulator-initial-mode = <3>;
    };
    ldo2_reg: LDO2 {
     regulator-name = "vdd_ldo2";
     regulator-min-microvolt = <1620000>;
     regulator-max-microvolt = <1980000>;
     regulator-always-on;
     regulator-boot-on;
     regulator-initial-mode = <3>;
    };

    ldo3_reg: LDO3 {
     regulator-name = "vdd_ldo3";
     regulator-min-microvolt = <1080000>;
     regulator-max-microvolt = <1350000>;
     regulator-boot-on;
     regulator-always-on;
     regulator-initial-mode = <3>;
    };

    ldo4_reg: LDO4 {
     regulator-name = "vqmmc";
     regulator-min-microvolt = <1800000>;
     regulator-max-microvolt = <2800000>;
     regulator-boot-on;
     regulator-ramp-delay = <12000>;
     regulator-initial-mode = <1>;
    };

    ldo5_reg: LDO5 {
     regulator-name = "vdd_ldo5";
     regulator-min-microvolt = <2250000>;
     regulator-max-microvolt = <3300000>;
     regulator-boot-on;
     regulator-always-on;
     regulator-initial-mode = <3>;
    };

    ldo6_reg: LDO6 {
     regulator-name = "vdd_ldo6";
     regulator-min-microvolt = <1350000>;
     regulator-max-microvolt = <1650000>;
     regulator-initial-mode = <1>;
    };

    ldo17_reg: LDO17 {
     regulator-name = "vdd_ldo17";
     regulator-min-microvolt = <1000000>;
     regulator-max-microvolt = <2375000>;
     regulator-initial-mode = <1>;
    };

    ldo18_reg: LDO18 {
     regulator-name = "vdd_ldo18";
     regulator-min-microvolt = <1800000>;
     regulator-max-microvolt = <3375000>;
     regulator-always-on;
     regulator-boot-on;
     regulator-initial-mode = <1>;
    };

    ldo19_reg: LDO19 {
     regulator-name = "vdd_ldo19";
     regulator-min-microvolt = <1000000>;
     regulator-max-microvolt = <2375000>;
     regulator-always-on;
     regulator-boot-on;
     regulator-initial-mode = <1>;
    };

    ldo20_reg: LDO20 {
     regulator-name = "vdd_ldo20";
     regulator-min-microvolt = <1800000>;
     regulator-max-microvolt = <3375000>;
     regulator-always-on;
     regulator-boot-on;
     regulator-initial-mode = <1>;
    };

    ldo21_reg: LDO21 {
     regulator-name = "VDDIO_1.8V_CAM";
     regulator-min-microvolt = <1800000>;
     regulator-max-microvolt = <1800000>;
    };

    ldo22_reg: LDO22 {
     regulator-name = "VDDAF_2.8V_CAM";
     regulator-min-microvolt = <2800000>;
     regulator-max-microvolt = <2800000>;
    };

    ldo23_reg: LDO23 {
     regulator-name = "vdd_ldo23";
     regulator-min-microvolt = <1000000>;
     regulator-max-microvolt = <2375000>;
     regulator-always-on;
     regulator-boot-on;
     regulator-initial-mode = <1>;
    };

    ldo24_reg: LDO24 {
     regulator-name = "codec_ldo24";
     regulator-min-microvolt = <1000000>;
     regulator-max-microvolt = <2375000>;
     regulator-boot-on;
     regulator-always-on;
     regulator-initial-mode = <1>;
    };

    ldo25_reg: LDO25 {
     regulator-name = "vdd_ldo25";
     regulator-min-microvolt = <1800000>;
     regulator-max-microvolt = <3375000>;
     regulator-initial-mode = <1>;
    };
   };
  };

  audio_codec_cod3025x: cod3025x@04 {
   compatible = "codec,cod3025x";
   reg = <0x04>;
   ten-bit-address;
   vdd-supply = <&ldo17_reg>;
   pinctrl-names = "default";
   pinctrl-0 = <&cod3025_irq>;
   interrupt-parent = <&gpa0>;
   gpios = <&gpa0 6 0xf>;
   mic-bias1-voltage = <3>;
   mic-bias2-voltage = <3>;
   mic-bias-ldo-voltage = <3>;
  };
 };

 s2803x: s2803x@148C0000 {
  pinctrl-names = "default", "idle";
  pinctrl-0 = <&i2s_pmic_bus &i2s_bt_bus>;
  pinctrl-1 = <&i2s_pmic_bus_idle &i2s_bt_bus_idle>;
  bck-mcko-mode;
  status = "okay";
 };

 i2s0: i2s@148E0000 {
  status = "okay";
 };

 audio_cp_dummy: cp_dummy {
  compatible = "samsung,cp_dummy";
  status = "okay";
 };

 audio_bt_dummy: bt_dummy {
  compatible = "samsung,bt_dummy";
  status = "okay";
 };

 audio_fm_dummy: fm_dummy {
  compatible = "samsung,fm_dummy";
  status = "okay";
 };

 audio_codec_dummy: dummy-codec {
  compatible = "samsung,dummy-codec";
  status = "okay";
 };

 sound {
  compatible = "samsung,universal3475-cod3025x";
  samsung,audio-cpu = <&i2s0
     &i2s0
     &audio_cp_dummy
     &audio_bt_dummy
     &audio_fm_dummy>;
  samsung,audio-codec = <&audio_codec_cod3025x
     &audio_codec_cod3025x
     &audio_codec_cod3025x
     &audio_codec_dummy
     &audio_codec_cod3025x>;
  samsung,auxdev = <&s2803x>;
  status = "okay";
  samsung,use-externel-jd;
 };

 hsi2c@13870000 {
  status = "okay";
  s2mu003@34 {
   compatible = "samsung,s2mu003mfd";
   reg = <0x34>;
   pinctrl-names = "default";
   pinctrl-0 = <&if_irq>;
   s2mu003,irq-gpio = <&gpa0 2 0>;

   regulators {
    s2mu003-buck1 {
     regulator-name = "VDDD_1.2V_CAM";
     regulator-min-microvolt = <1200000>;
     regulator-max-microvolt = <1200000>;
    };
    s2mu003-ldo1 {
     regulator-name = "VDDA_2.8V_CAM";
     regulator-min-microvolt = <2800000>;
     regulator-max-microvolt = <2800000>;
    };
   };
  };

  leds {
   torch-gpio = <&gpd0 7 0>;
   flash-gpio = <&gpd2 3 0>;

   status = "okay";
   s2mu003-leds1 {
    ledname = "leds-sec1";
    id = <0>;
    brightness = <0x17>;
    timeout = <0x0>;
    max-brightness = <0x15>;
   };

   s2mu003-leds2 {
    ledname = "leds-sec2";
    id = <1>;
    brightness = <0x02>;
    timeout = <0x0>;
    max-brightness = <0xf>;
   };
  };
 };

 i2c@13860000 {
  status = "okay";
  samsung,i2c-sda-delay = <100>;
  samsung,i2c-max-bus-freq = <400000>;
  #address-cells = <1>;
  #size-cells = <0>;
  s2mu003-fuelgauge@35 {
   compatible = "samsung,s2mu003-fuelgauge";
   reg = <0x35>;
   fuelgauge,fuel_alert_soc = <1>;
   fuelgauge,capacity_max = <1000>;
   fuelgauge,capacity_max_margin = <30>;
   fuelgauge,capacity_min = <0>;
   fuelgauge,capacity_calculation_type = <28>;
   fuelgauge,repeated_fuelalert;
   fuelgauge,type_str = "SDI";
  };
 };

 battery {
  battery,charger_name = "sec-charger";
  battery,fuelgauge_name = "sec-fuelgauge";

  battery,input_current_limit = <1800 0 0 1000 460 900 1000 460 1000 0 820 1900 1000 0 0 400 700 1300 300 1000 1500 0 1667 1000 80 1800>;
  battery,fast_charging_current = <2100 0 0 1000 460 1200 1000 460 1200 0 1000 1600 1000 0 0 400 700 1300 300 1000 1500 0 3150 1000 80 1800>;
  battery,full_check_current_1st = <350 0 0 250 250 250 250 250 250 0 250 250 250 0 0 350 350 350 350 350 350 0 350 350 0 350>;
  battery,full_check_current_2nd = <3000 0 0 3000 3000 3000 3000 3000 3000 0 3000 3000 0 0 0 3000 3000 3000 3000 3000 3000 0 3000 3000 3000 3000>;

 };

 s2mu003-charger {
  status = "disable";
  compatible = "samsung,s2mu003-charger";
  battery,is_1MHz_switching = <1>;
  battery,is_fixed_switching = <1>;
  battery,chg_gpio_en = <0>;
  battery,chg_polarity_en = <0>;
  battery,chg_gpio_status = <0>;
  battery,chg_polarity_status = <0>;
  battery,chg_float_voltage = <4350>;
 };

 hsi2c@13880000 {
  status = "okay";
  muic-s2mm001@25 {
   compatible = "sec-muic,i2c";
   reg = <0x25>;
   pinctrl-names = "default";
   muic,muic_int = <&gpa0 4 0>;
  };
 };

 ion {
  compatible = "samsung,exynos5430-ion";

  contig-names = "common",
          "mfc_sh",
          "g2d_wfd",
          "video",
          "sectbl",
          "mfc_fw",
          "mfc_nfw",
          "secdma";

  contig = <0 0x600000 0x0>,
           <2 0x100000 0x0>,
           <10 0x800000 0x0>,
           <11 0x3000000 0x0>,
           <9 0x100000 0x0>,
           <8 0x100000 0x0>,
           <12 0x100000 0x0>,
           <13 0x20000 0x0>;

  contig-isolate_on_boot = <0>, <2>, <8>,
       <9>, <10>, <11>, <12>, <13>;

  ion_noncontig_heap {
   id-type = <0 0>;
  };

  exynos_contig_heap {
   id-type = <4 6>;
  };
 };

 pinctrl@139B0000 {
  gpa0_pull_up: gpa0_pull_up {
   samsung,pins = "gpa0-0", "gpa0-1";
   samsung,pin-function = <0xf>;
   samsung,pin-pud = <3>;
   samsung,pin-drv = <0>;
  };
 };

 gpio_keys {
  compatible = "gpio-keys";
  #address-cells = <1>;
  #size-cells = <0>;
  pinctrl-names = "default";
  pinctrl-0 = <&gpa0_pull_up>;
  button@1 {
   label = "gpio-keys: KEY_POWER";
   interrupts = <4 0 0>;
   interrupt-parent = <&gpa1>;
   linux,code = <116>;
   gpios = <&gpa1 4 0xf>;
   gpio-key,wakeup = <1>;
  };
  button@2 {
   label = "gpio-keys: KEY_VOLUMEDOWN";
   interrupts = <0 0 0>;
   interrupt-parent = <&gpa0>;
   linux,code = <114>;
   gpios = <&gpa0 0 0xf>;
  };
  button@3 {
   label = "gpio-keys: KEY_VOLUMEUP";
   interrupts = <1 0 0>;
   interrupt-parent = <&gpa0>;
   linux,code = <115>;
   gpios = <&gpa0 1 0xf>;
  };
 };

 dwmmc0@13540000 {
  status = "okay";
  num-slots = <1>;
  broken-cd;
  use-smu;
  fixed_volt;
  only_once_tune;
  clock-gate;
  enable-cclk-on-suspend;
  supports-highspeed;
  supports-hs200-mode;
  supports-ddr200-mode;
  supports-ddr200-enhanced-strobe;
  enable-ulp-mode;
  ulp-mux-sel-hs400;
  enable-cache-control;
  use-fine-tuning;
  extra_tuning;
  bypass-for-allpass;
  use-enable-shift;
  desc-size = <4>;
  fifo-depth = <0x40>;
  qos_int_level = <138000>;
  card-detect-delay = <200>;


  samsung,dw-mshc-txdt-crc-timer-fastlimit = <0x12>;

  samsung,dw-mshc-txdt-crc-timer-initval = <0x14>;

  samsung,dw-mshc-ddr200-delay-line = <0x50>;



  samsung,dw-mshc-ulp-txdt-crc-timer-fastlimit = <0x34>;

  samsung,dw-mshc-ulp-txdt-crc-timer-initval = <0x38>;

  samsung,dw-mshc-ulp-ddr200-delay-line = <0x50>;

  samsung,dw-mshc-ciu-div = <3>;

  samsung,dw-mshc-sdr-timing = <3 0 2 0>;
  samsung,dw-mshc-sdr-hs-timing = <3 0 2 1>;
  samsung,dw-mshc-ddr-timing = <3 0 4 2>;
  samsung,dw-mshc-hs200-timing = <3 0 3 0>;
  samsung,dw-mshc-ddr200-timing = <1 0 4 0>;
  samsung,dw-mshc-ddr200-ulp-timing = <3 0 4 0>;
  clk_pin = "gpr0-0";
  clk_addr = "13750000.pinctrl";
  clk_val = <0x2>;
  clk_str_num = <4>;
  num-ref-clks = <10>;
  ciu_clkin = <22 42 42 84 167 84 167 334 334 167>;

  pinctrl-names = "default";
  pinctrl-0 = <&sd0_clk &sd0_cmd &sd0_rdqs &sd0_bus1 &sd0_bus4 &sd0_bus8>;
  slot@0 {
   reg = <0>;
   bus-width = <8>;
  };
 };

 dwmmc1@13550000 {
  status = "okay";
  num-slots = <1>;
  cd-type-external;
  fixed_volt;
  clock-gate;
  enable-cclk-on-suspend;
  caps-control;
  supports-highspeed;
  supports-sdr104-mode;
  supports-highspeed;
  use-fine-tuning;
  bypass-for-allpass;
  fifo-depth = <0x40>;
  card-detect-delay = <200>;
  qos_int_level = <138000>;
  samsung,dw-mshc-ciu-div = <3>;
  samsung,dw-mshc-sdr-timing = <3 0 2 0>;
  samsung,dw-mshc-ddr-timing = <3 0 3 2>;
  clk_pin = "gpr2-0";
  clk_addr = "13750000.pinctrl";
  clk_val = <0x2>;
  clk_str_num = <4>;
  num-ref-clks = <8>;
  ciu_clkin = <22 42 42 84 167 84 167 334>;
  pinctrl-names = "default";
  pinctrl-0 = <&sd1_clk &sd1_cmd &sd1_bus1 &sd1_bus4 &dwmmc1_cd_ext_irq &cfg_wlanen>;

  cd-gpio = <&gpa1 5 0xf>;
  slot@0 {
   reg = <0>;
   bus-width = <4>;
  };
 };

 dwmmc2@13560000 {
  status = "okay";
  num-slots = <1>;
  bypass-smu;
  clock-gate;
  enable-cclk-on-suspend;
  caps-control;
  supports-highspeed;
  supports-sdr104-mode;
  fix-fmp-size-mismatch;
  not-allow-single-dma;
  use-fine-tuning;
  desc-size = <4>;
  bypass-for-allpass;
  fifo-depth = <0x40>;
  card-detect-delay = <200>;
  qos_int_level = <138000>;
  samsung,dw-mshc-ciu-div = <3>;
  samsung,dw-mshc-sdr-timing = <3 0 2 0>;
  samsung,dw-mshc-ddr-timing = <3 0 3 2>;
  clk_pin = "gpr4-0";
  clk_addr = "13750000.pinctrl";
  clk_val = <0x2>;
  clk_str_num = <4>;
  num-ref-clks = <8>;
  ciu_clkin = <22 42 42 84 167 84 167 334>;
  pinctrl-names = "default";
  pinctrl-0 = <&sd2_clk &sd2_cmd &sd2_bus1 &sd2_bus4 &dwmmc2_cd_ext_irq>;

  cd-gpio = <&gpa1 3 0xf>;
  slot@0 {
   reg = <0>;
   bus-width = <4>;
   disable-wp;
  };
 };

 pinctrl@139B0000 {
  dwmmc1_cd_ext_irq: dwmmc1_cd_ext_irq {
      samsung,pins = "gpa1-5";
      samsung,pin-function = <0xf>;
      samsung,pin-pud = <1>;
      samsung,pin-drv = <0>;
  };

  dwmmc2_cd_ext_irq: dwmmc2_cd_ext_irq {
      samsung,pins = "gpa1-3";
      samsung,pin-function = <0xf>;
      samsung,pin-pud = <0>;
      samsung,pin-drv = <0>;
  };
 };

 decon_fb@14830000 {





  status = "okay";
 };

 dsim_0: dsim@14800000 {
  lcd_info = <&s6d78a>;
  decon_board = <&decon_board_list>;


  status = "okay";


  data_lane_cnt = <2>;
 };

 decon_board_list: decon_board_list {
  dsim_set_panel_power_enable {
   type = "gpio,high", "delay,usleep";
   gpios = <&gpd0 5 0x1>;
   delay = <10000 11000>;
  };
  dsim_set_panel_power_disable {
   type = "gpio,low", "delay,usleep", "gpio,low", "delay,usleep";
   gpios = <&gpd2 2 0x1>, <&gpd0 5 0x1>;
   delay = <10000 11000>, <10000 11000>;
  };
  dsim_reset_panel {
   type = "gpio,high", "delay,usleep", "gpio,low", "delay,usleep", "gpio,high", "delay,usleep";
   gpios = <&gpd2 2 0x1>, <&gpd2 2 0x1>, <&gpd2 2 0x1>;
   delay = <5000 6000>, <5000 6000>, <10000 11000>;
  };
 };

 s6d78a: s6d78a_qhd {
  panel_name = "s6d78a";
  resolution = <540 960>;
  size = <71 114>;
  timing,refresh = <60>;

  timing,h-porch = <0xA 0xA 0xE>;

  timing,v-porch = <0x6 0x8 0x2>;
  timing,dsi-hs-clk = <500>;
  timing,dsi-escape-clk = <20>;
 };

 usb_notifier {
  compatible = "samsung,usb-notifier";
  udc = <&udc>;
 };

 fimc_is_module_4h5: fimc-is_sensor_4h5@0 {
  compatible = "samsung,sensor-module-4h5";

  pinctrl-names = "pin0", "pin1";
  pinctrl-0 = <&fimc_is_mclk0_fn>;
  pinctrl-1 = <&fimc_is_mclk0_in>;

  position = <0>;
  id = <0>;
  mclk_ch = <0>;
  sensor_i2c_ch = <0>;
  sensor_i2c_addr = <0x37>;

  gpio_reset = <&gpd0 2 0x1>;
  gpio_core_en = <&gpd1 0 0x1>;
  gpio_mclk = <&gpe0 0 0x1>;
  status = "okay";

  af {
   product_name = <2>;
   i2c_addr = <0x0C>;
   i2c_ch = <0>;
  };
 };

 fimc_is_module_6b2: fimc-is_sensor_6b2@0 {
  compatible = "samsung,sensor-module-6b2";

  pinctrl-names = "pin0", "pin1";
  pinctrl-0 = <&fimc_is_mclk1_fn>;
  pinctrl-1 = <&fimc_is_mclk1_in>;

  position = <1>;
  id = <1>;
  mclk_ch = <1>;
  sensor_i2c_ch = <1>;
  sensor_i2c_addr = <0x35>;

  gpio_reset = <&gpd0 4 0x1>;
  gpio_standby = <&gpd2 3 0x1>;
  gpio_mclk = <&gpe0 1 0x1>;
  status = "okay";
 };

 hsi2c_7: hsi2c@138A0000 {
  gpios = <&gpf0 0 0 &gpf0 1 0>;
  status = "okay";
  samsung,i2c-sda-delay = <100>;
  samsung,i2c-max-bus-freq = <400000>;

  pinctrl-names = "default";
  pinctrl-0 = <&hs_i2c7_bus>;

  fimc-is-4h5@20 {
   compatible = "samsung,exynos5-fimc-is-cis-4h5";
   reg = <0x37>;
   id = <0>;
   setfile = "setA";
  };

  fimc-is-actuator@0C {
   compatible = "samsung,exynos5-fimc-is-actuator-dw9804";
   reg = <0x0C>;
   id = <0>;
  };
 };

 hsi2c_8: hsi2c@138B0000 {
  gpios = <&gpf0 2 0 &gpf0 3 0>;
  status = "okay";
  samsung,i2c-sda-delay = <100>;
  samsung,i2c-max-bus-freq = <400000>;

  pinctrl-names = "default";
  pinctrl-0 = <&hs_i2c8_bus>;

  fimc-is-6b2@35 {
   compatible = "samsung,exynos5-fimc-is-cis-6b2";
   reg = <0x35>;
   id = <1>;
   setfile = "setB";
  };
 };

 fimc_is_sensor0: fimc_is_sensor@14410000 {
  scenario = <0>;
  id = <0>;
  mclk_ch = <0>;
  csi_ch = <0>;
  flite_ch = <0>;
  i2c_ch = <0>;
  i2c_addr = <0x2D>;
  is_bns = <0>;
  status = "okay";
 };

 fimc_is_sensor1: fimc_is_sensor@14411000 {
  scenario = <0>;
  id = <1>;
  mclk_ch = <1>;
  csi_ch = <0>;
  flite_ch = <0>;
  i2c_ch = <0>;
  i2c_addr = <0x2D>;
  is_bns = <0>;
  status = "okay";
 };

 fimc_is@14400000 {
  rear_sensor_id = <13>;
  front_sensor_id = <7>;
# 880 "arch/arm/boot/dts/exynos3475-universal3475.dts"
  fimc_is_dvfs {
   default_int = <334000>;
   default_cam = <0>;
   default_mif = <666000>;
   default_i2c = <0>;

   front_preview_int = <333000>;
   front_preview_cam = <0>;
   front_preview_mif = <666000>;
   front_preview_i2c = <0>;

   front_capture_int = <333000>;
   front_capture_cam = <0>;
   front_capture_mif = <666000>;
   front_capture_i2c = <0>;

   front_video_int = <333000>;
   front_video_cam = <0>;
   front_video_mif = <666000>;
   front_video_i2c = <0>;

   front_video_whd_int = <334000>;
   front_video_whd_cam = <0>;
   front_video_whd_mif = <666000>;
   front_video_whd_i2c = <0>;

   front_video_capture_int = <333000>;
   front_video_capture_cam = <0>;
   front_video_capture_mif = <666000>;
   front_video_capture_i2c = <0>;

   front_video_whd_capture_int = <334000>;
   front_video_whd_capture_cam = <0>;
   front_video_whd_capture_mif = <666000>;
   front_video_whd_capture_i2c = <0>;

   front_vt1_int = <333000>;
   front_vt1_cam = <0>;
   front_vt1_mif = <666000>;
   front_vt1_i2c = <0>;

   front_vt2_int = <333000>;
   front_vt2_cam = <0>;
   front_vt2_mif = <666000>;
   front_vt2_i2c = <0>;

   rear_preview_fhd_int = <334000>;
   rear_preview_fhd_cam = <0>;
   rear_preview_fhd_mif = <666000>;
   rear_preview_fhd_i2c = <0>;

   rear_preview_whd_int = <334000>;
   rear_preview_whd_cam = <0>;
   rear_preview_whd_mif = <666000>;
   rear_preview_whd_i2c = <0>;

   rear_preview_uhd_int = <334000>;
   rear_preview_uhd_cam = <0>;
   rear_preview_uhd_mif = <666000>;
   rear_preview_uhd_i2c = <0>;

   rear_capture_int = <334000>;
   rear_capture_cam = <0>;
   rear_capture_mif = <666000>;
   rear_capture_i2c = <0>;

   rear_video_fhd_int = <334000>;
   rear_video_fhd_cam = <0>;
   rear_video_fhd_mif = <666000>;
   rear_video_fhd_i2c = <0>;

   rear_video_uhd_int = <334000>;
   rear_video_uhd_cam = <0>;
   rear_video_uhd_mif = <666000>;
   rear_video_uhd_i2c = <0>;
   rear_video_fhd_capture_int = <334000>;
   rear_video_fhd_capture_cam = <0>;
   rear_video_fhd_capture_mif = <666000>;
   rear_video_fhd_capture_i2c = <0>;

   rear_video_uhd_capture_int = <334000>;
   rear_video_uhd_capture_cam = <0>;
   rear_video_uhd_capture_mif = <666000>;
   rear_video_uhd_capture_i2c = <0>;

   dual_preview_int = <334000>;
   dual_preview_cam = <0>;
   dual_preview_mif = <666000>;
   dual_preview_i2c = <0>;

   dual_capture_int = <334000>;
   dual_capture_cam = <0>;
   dual_capture_mif = <666000>;
   dual_capture_i2c = <0>;

   dual_video_int = <334000>;
   dual_video_cam = <0>;
   dual_video_mif = <666000>;
   dual_video_i2c = <0>;

   dual_video_capture_int = <334000>;
   dual_video_capture_cam = <0>;
   dual_video_capture_mif = <666000>;
   dual_video_capture_i2c = <0>;

   preview_high_speed_fps_int = <334000>;
   preview_high_speed_fps_cam = <0>;
   preview_high_speed_fps_mif = <666000>;
   preview_high_speed_fps_i2c = <0>;

   video_high_speed_fps_int = <334000>;
   video_high_speed_fps_cam = <0>;
   video_high_speed_fps_mif = <666000>;
   video_high_speed_fps_i2c = <0>;

   max_int = <334000>;
   max_cam = <0>;
   max_mif = <666000>;
   max_i2c = <0>;
  };
 };

};
